# STM32H7x7_CM7 register map
File version: 1.0
CPU: CM7 r0p1, little endian, MPU, FPU, 4 interrupt priority bits
Registers are 32-bit, read-write, reset 0x0 unless marked. A register's access mark holds for its fields unless they carry their own. Offsets are from the block's base; [hi:lo] are bit positions; {n}, {i} and the like mark numbered series; 'fields as' and 'values as' point back to an identical list.

## HSEM
Base 0x58026400
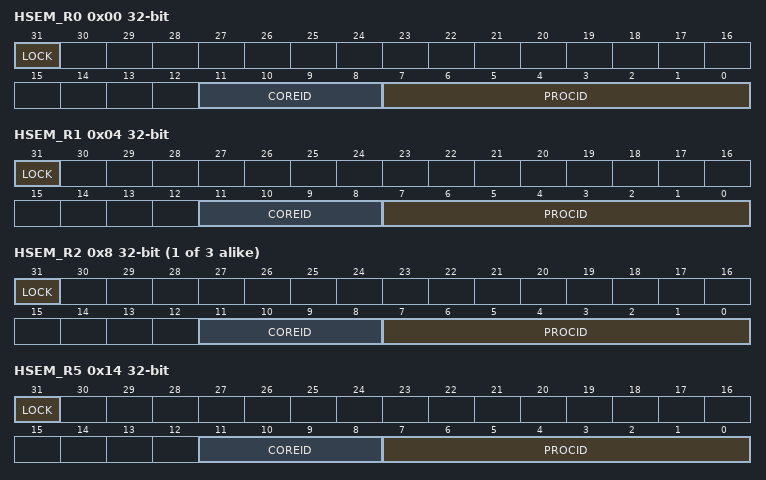
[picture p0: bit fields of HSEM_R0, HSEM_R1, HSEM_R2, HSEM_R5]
0x00 HSEM_R0 — HSEM register HSEM_R0 HSEM_R31
  [31] LOCK — Lock indication
  [11:8] COREID — Semaphore CoreID
  [7:0] PROCID — Semaphore ProcessID
0x04 HSEM_R1 — HSEM register HSEM_R0 HSEM_R31
  fields as HSEM_R0
{0x0+4i} HSEM_R{i} (i=2..4) — HSEM register HSEM_R0 HSEM_R31
  [31] LOCK — Lock indication
  [11:8] COREID — Semaphore CoreID.
  [7:0] PROCID — Semaphore ProcessID
0x14 HSEM_R5 — HSEM register HSEM_R0 HSEM_R31
  fields as HSEM_R0
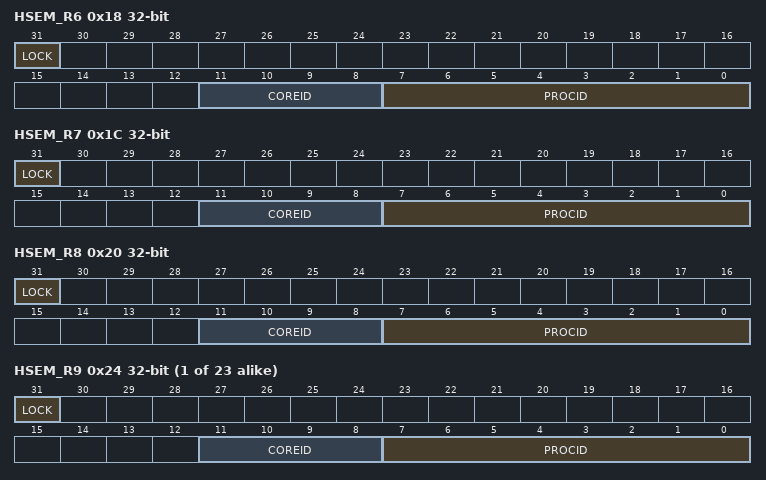
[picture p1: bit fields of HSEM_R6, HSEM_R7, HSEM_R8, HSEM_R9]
0x18 HSEM_R6 — HSEM register HSEM_R0 HSEM_R31
  fields as HSEM_R2
0x1C HSEM_R7 — HSEM register HSEM_R0 HSEM_R31
  fields as HSEM_R0
0x20 HSEM_R8 — HSEM register HSEM_R0 HSEM_R31
  fields as HSEM_R2
{0x0+4i} HSEM_R{i} (i=9..31) — HSEM register HSEM_R0 HSEM_R31
  fields as HSEM_R0
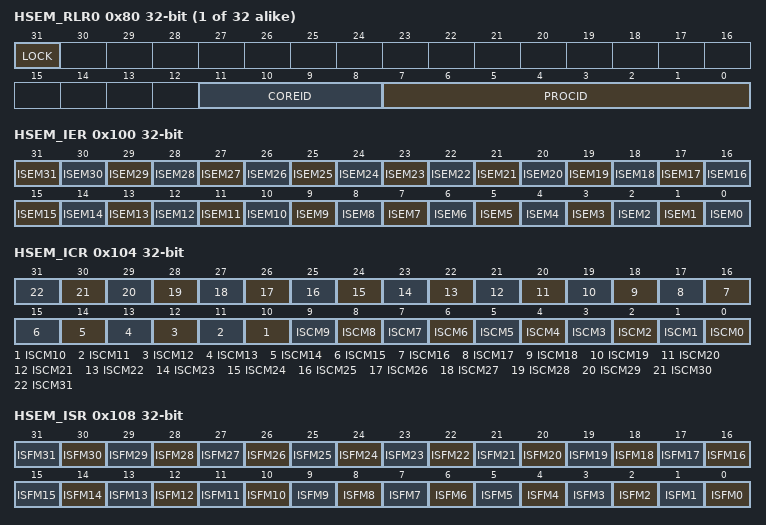
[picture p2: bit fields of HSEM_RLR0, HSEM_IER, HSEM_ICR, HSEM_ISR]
{0x80+4i} HSEM_RLR{i} ro (i=0..31) — HSEM Read lock register
  fields as HSEM_R0
0x100 HSEM_IER — HSEM Interrupt enable register
  [31] ISEM31 — Interrupt(N) semaphore n enable bit.
  [n] ISEM{n} (n=0..30) — Interrupt semaphore n enable bit
0x104 HSEM_ICR wo — HSEM Interrupt clear register
  [n] ISCM{n} (n=0..31) — Interrupt(N) semaphore n clear bit
0x108 HSEM_ISR ro — HSEM Interrupt status register
  [n] ISFM{n} (n=0..31) — Interrupt(N) semaphore n status bit before enable (mask).
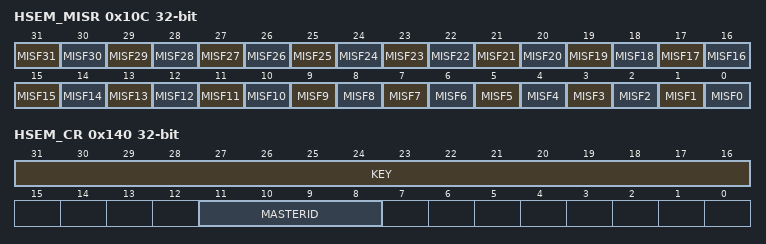
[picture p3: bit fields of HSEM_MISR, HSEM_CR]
0x10C HSEM_MISR ro — HSEM Masked interrupt status register
  [n] MISF{n} (n=3..31) — masked interrupt(N) semaphore n status bit after enable (mask).
  [2] MISF2 — Interrupt(N) semaphore n status bit before enable (mask)
  [1] MISF1 — Interrupt(N) semaphore n status bit before enable (mask)
  [0] MISF0 — Interrupt(N) semaphore n status bit before enable (mask)
0x140 HSEM_CR wo — HSEM Clear register
  [31:16] KEY — Semaphore clear Key
  [11:8] MASTERID — MasterID of semaphores to be cleared
0x144 HSEM_KEYR — HSEM Interrupt clear register
  [31:16] KEY — Semaphore Clear Key

## JPEG
Base 0x52003000
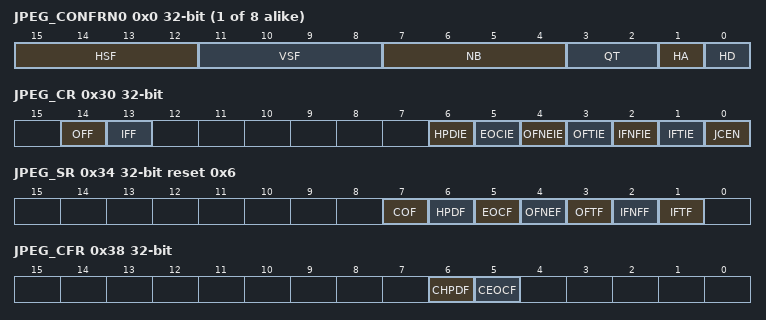
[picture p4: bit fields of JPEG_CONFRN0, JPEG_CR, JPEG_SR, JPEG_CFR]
{0x0+4i} JPEG_CONFRN{i} (i=0..7) — JPEG codec configuration register 4-7
  [15:12] HSF — Horizontal Sampling Factor Horizontal sampling factor for component i.
  [11:8] VSF — Vertical Sampling Factor Vertical sampling factor for component i.
  [7:4] NB — Number of Block Number of data units minus 1 that belong to a particular color in the MCU.
  [3:2] QT — Quantization Table Selects quantization table associated with a color component.
  [1] HA — Huffman AC Selects the Huffman table for encoding the AC coefficients.
  [0] HD — Huffman DC Selects the Huffman table for encoding the DC coefficients.
0x30 JPEG_CR access per field — JPEG control register
  [14] OFF ro — Output FIFO Flush This bit flush the output FIFO. This bit is always read as 0.
  [13] IFF ro — Input FIFO Flush This bit flush the input FIFO. This bit is always read as 0.
  [6] HPDIE rw — Header Parsing Done Interrupt Enable This bit enables the interrupt generation on the Header Parsing Operation.
  [5] EOCIE rw — End of Conversion Interrupt Enable This bit enables the interrupt generation on the end of conversion.
  [4] OFNEIE rw — Output FIFO Not Empty Interrupt Enable This bit enables the interrupt generation when output FIFO is not empty.
  [3] OFTIE rw — Output FIFO Threshold Interrupt Enable This bit enables the interrupt generation when output FIFO reach the threshold.
  [2] IFNFIE rw — Input FIFO Not Full Interrupt Enable This bit enables the interrupt generation when input FIFO is not empty.
  [1] IFTIE rw — Input FIFO Threshold Interrupt Enable This bit enables the interrupt generation when input FIFO reach the threshold.
  [0] JCEN rw — JPEG Core Enable Enable the JPEG codec Core.
0x34 JPEG_SR ro reset 0x6 — JPEG status register
  [7] COF — Codec Operation Flag This bit is set when when a JPEG codec operation is on going (encoding or decoding).
  [6] HPDF — Header Parsing Done Flag This bit is set in decode mode when the JPEG codec has finished the parsing of the headers and the internal registers have been updated.
  [5] EOCF — End of Conversion Flag This bit is set when the JPEG codec core has finished the encoding or the decoding process and than last data has been sent to the output FIFO.
  [4] OFNEF — Output FIFO Not Empty Flag This bit is set when the output FIFO is not empty (a data is available).
  [3] OFTF — Output FIFO Threshold Flag This bit is set when the output FIFO is not empty and has reach its threshold.
  [2] IFNFF — Input FIFO Not Full Flag This bit is set when the input FIFO is not full (a data can be written).
  [1] IFTF — Input FIFO Threshold Flag This bit is set when the input FIFO is not full and is bellow its threshold.
0x38 JPEG_CFR — JPEG clear flag register
  [6] CHPDF — Clear Header Parsing Done Flag Writing 1 clears the Header Parsing Done Flag of the JPEG Status Register.
  [5] CEOCF — Clear End of Conversion Flag Writing 1 clears the End of Conversion Flag of the JPEG Status Register.
0x40 JPEG_DIR wo — JPEG data input register
  [31:0] DATAIN — Data Input FIFO Input FIFO data register.
0x44 JPEG_DOR ro — JPEG data output register
  [31:0] DATAOUT — Data Output FIFO Output FIFO data register.
